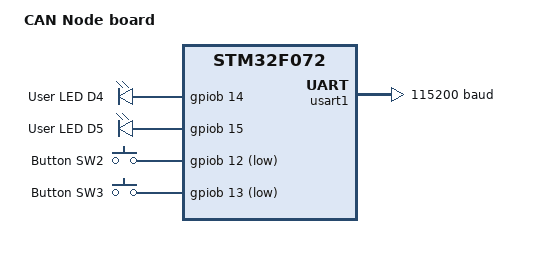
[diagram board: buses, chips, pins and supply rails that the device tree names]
/*
 * Copyright (c) 2018 Josef Raschen
 *
 * SPDX-License-Identifier: Apache-2.0
 */

/dts-v1/;
#include <st/stm32f072.dtsi>

/ {
	model = "CAN Node board";
	compatible = "raschen-elektronik,cannode", "st,stm32f072";

	chosen {
		zephyr,console = &usart1;
		zephyr,sram = &sram0;
		zephyr,flash = &flash0;
	};


	leds {
		compatible = "gpio-leds";
		led_d4: led@0 {
			gpios = <&gpiob 14 GPIO_INT_ACTIVE_HIGH>;
			label = "User LED D4";
		};
		led_d5: led@1 {
			gpios = <&gpiob 15 GPIO_INT_ACTIVE_HIGH>;
			label = "User LED D5";
		};
	};

	gpio_keys {
		compatible = "gpio-keys";
		switch_sw2: button@0 {
			label = "Button SW2";
			gpios = <&gpiob 12 GPIO_INT_ACTIVE_LOW>;
		};
		switch_sw3: button@1 {
			label = "Button SW3";
			gpios = <&gpiob 13 GPIO_INT_ACTIVE_LOW>;
		};
	};

	aliases {
		led0 = &led_d4;
		led1 = &led_d5;
		sw0 = &switch_sw2;
		sw1 = &switch_sw3;
	};
};

&usart1 {
	current-speed = <115200>;
	pinctrl-0 = <&usart1_pins_a>;
	pinctrl-names = "default";
	status = "ok";
};
